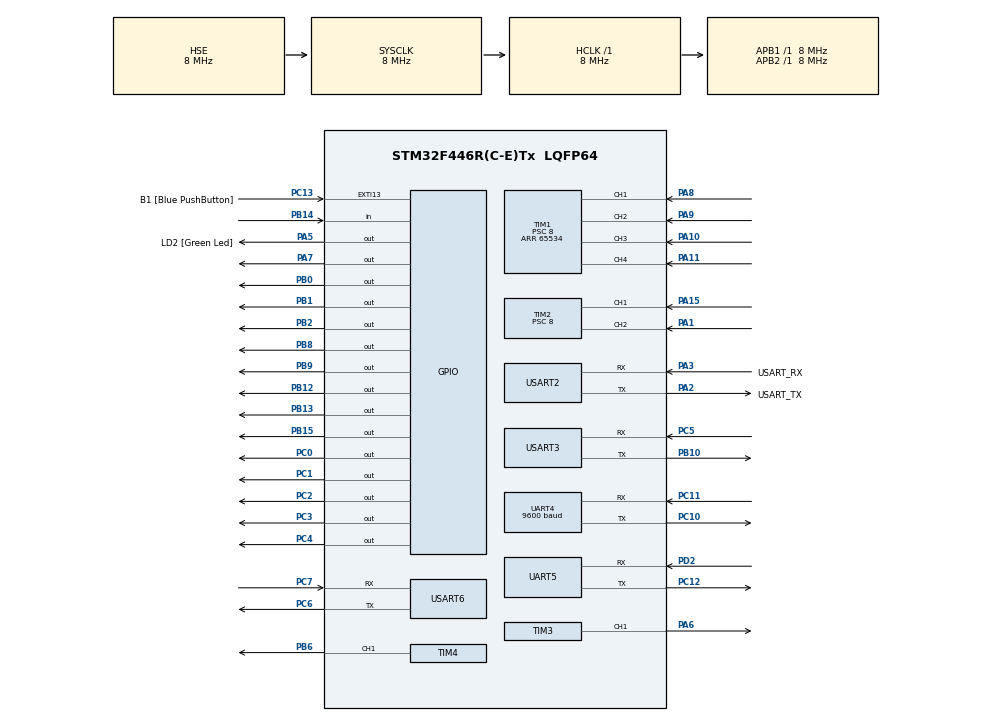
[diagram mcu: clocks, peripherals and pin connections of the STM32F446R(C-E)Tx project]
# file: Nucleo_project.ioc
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FREERTOS.HEAP_NUMBER=1
FREERTOS.Tasks01=defaultTask,0,128,StartDefaultTask,Default,NULL,Dynamic,NULL,NULL
FREERTOS.configMAX_PRIORITIES=10
FREERTOS.configUSE_NEWLIB_REENTRANT=1
Mcu.Family=STM32F4
Mcu.Name=STM32F446R(C-E)Tx
Mcu.Package=LQFP64
NVIC.PriorityGroup=NVIC_PRIORITYGROUP_4
NVIC.TIM1_CC_IRQn=true\:5\:0\:false\:false\:true\:true\:true\:true\:true
NVIC.TIM8_TRG_COM_TIM14_IRQn=true\:15\:0\:false\:false\:true\:false\:false\:true\:true
NVIC.TimeBase=TIM8_TRG_COM_TIM14_IRQn
NVIC.TimeBaseIP=TIM14
PA0-WKUP.Mode=SYS_WakeUp0
PA0-WKUP.Signal=SYS_WKUP0
PA1.Signal=S_TIM2_CH2
PA10.Signal=S_TIM1_CH3
PA11.Signal=S_TIM1_CH4
PA13.GPIO_Label=TMS
PA13.Mode=Serial_Wire
PA13.Signal=SYS_JTMS-SWDIO
PA14.GPIO_Label=TCK
PA14.Mode=Serial_Wire
PA14.Signal=SYS_JTCK-SWCLK
PA15.Signal=S_TIM2_CH1_ETR
PA2.GPIO_Label=USART_TX
PA2.Mode=Asynchronous
PA2.Signal=USART2_TX
PA3.GPIO_Label=USART_RX
PA3.Mode=Asynchronous
PA3.Signal=USART2_RX
PA5.GPIO_Label=LD2 [Green Led]
PA5.Signal=GPIO_Output
PA6.Signal=S_TIM3_CH1
PA7.Signal=GPIO_Output
PA8.Signal=S_TIM1_CH1
PA9.Signal=S_TIM1_CH2
PB0.Signal=GPIO_Output
PB1.Signal=GPIO_Output
PB10.Mode=Asynchronous
PB10.Signal=USART3_TX
PB12.Signal=GPIO_Output
PB13.Signal=GPIO_Output
PB14.Signal=GPIO_Input
PB15.Signal=GPIO_Output
PB2.Signal=GPIO_Output
PB3.GPIO_Label=SWO
PB3.Signal=SYS_JTDO-SWO
PB6.Signal=S_TIM4_CH1
PB8.Signal=GPIO_Output
PB9.Signal=GPIO_Output
PC0.Signal=GPIO_Output
PC1.Signal=GPIO_Output
PC10.Mode=Asynchronous
PC10.Signal=UART4_TX
PC11.Mode=Asynchronous
PC11.Signal=UART4_RX
PC12.Mode=Asynchronous
PC12.Signal=UART5_TX
PC13.GPIO_Label=B1 [Blue PushButton]
PC13.GPIO_ModeDefaultEXTI=GPIO_MODE_IT_FALLING
PC13.Signal=GPXTI13
PC14-OSC32_IN.Signal=RCC_OSC32_IN
PC15-OSC32_OUT.Signal=RCC_OSC32_OUT
PC2.Signal=GPIO_Output
PC3.Signal=GPIO_Output
PC4.Signal=GPIO_Output
PC5.Mode=Asynchronous
PC5.Signal=USART3_RX
PC6.Mode=Asynchronous
PC6.Signal=USART6_TX
PC7.Mode=Asynchronous
PC7.Signal=USART6_RX
PD2.Mode=Asynchronous
PD2.Signal=UART5_RX
PH0-OSC_IN.Mode=HSE-External-Oscillator
PH0-OSC_IN.Signal=RCC_OSC_IN
PH1-OSC_OUT.Mode=HSE-External-Oscillator
PH1-OSC_OUT.Signal=RCC_OSC_OUT
ProjectManager.HeapSize=0x200
ProjectManager.StackSize=0x400
ProjectManager.TargetToolchain=STM32CubeIDE
RCC.48MHZClocksFreq_Value=84000000
RCC.AHBFreq_Value=8000000
RCC.APB1Freq_Value=8000000
RCC.APB1TimFreq_Value=8000000
RCC.APB2Freq_Value=8000000
RCC.APB2TimFreq_Value=8000000
RCC.CortexFreq_Value=8000000
RCC.FLatency-AdvancedSettings=FLASH_LATENCY_0
RCC.HCLKFreq_Value=8000000
RCC.HSE_VALUE=8000000
RCC.HSI_VALUE=16000000
RCC.PLLM=4
RCC.PLLN=90
RCC.PLLSourceVirtual=RCC_PLLSOURCE_HSE
RCC.SYSCLKFreq_VALUE=8000000
RCC.SYSCLKSource=RCC_SYSCLKSOURCE_HSE
RCC.USBFreq_Value=90000000
RCC.VCOOutputFreq_Value=180000000
SH.S_TIM1_CH1.0=TIM1_CH1,Input_Capture1_from_TI1
SH.S_TIM1_CH2.0=TIM1_CH2,Input_Capture2_from_TI2
SH.S_TIM1_CH3.0=TIM1_CH3,Input_Capture3_from_TI3
SH.S_TIM1_CH4.0=TIM1_CH4,Input_Capture4_from_TI4
SH.S_TIM2_CH1_ETR.0=TIM2_CH1,Input_Capture1_from_TI1
SH.S_TIM2_CH2.0=TIM2_CH2,Input_Capture2_from_TI2
SH.S_TIM3_CH1.0=TIM3_CH1,PWM Generation1 CH1
SH.S_TIM4_CH1.0=TIM4_CH1,PWM Generation1 CH1
TIM1.Channel-Input_Capture1_from_TI1=TIM_CHANNEL_1
TIM1.Channel-Input_Capture2_from_TI2=TIM_CHANNEL_2
TIM1.Channel-Input_Capture3_from_TI3=TIM_CHANNEL_3
TIM1.Channel-Input_Capture4_from_TI4=TIM_CHANNEL_4
TIM1.CounterMode=TIM_COUNTERMODE_UP
TIM1.Period=65534
TIM1.Prescaler=8
TIM2.Channel-Input_Capture1_from_TI1=TIM_CHANNEL_1
TIM2.Channel-Input_Capture2_from_TI2=TIM_CHANNEL_2
TIM2.Period=65434
TIM2.Prescaler=8
TIM3.AutoReloadPreload=TIM_AUTORELOAD_PRELOAD_ENABLE
TIM3.Channel-PWM\ Generation1\ CH1=TIM_CHANNEL_1
TIM3.Period=20000
TIM3.Prescaler=8
TIM4.AutoReloadPreload=TIM_AUTORELOAD_PRELOAD_ENABLE
TIM4.Channel-PWM\ Generation1\ CH1=TIM_CHANNEL_1
TIM4.Period=100
TIM4.Prescaler=4
UART4.BaudRate=9600
UART4.VirtualMode=Asynchronous
UART5.VirtualMode=Asynchronous
USART2.VirtualMode=VM_ASYNC
USART3.VirtualMode=VM_ASYNC
USART6.VirtualMode=VM_ASYNC
VP_FREERTOS_VS_CMSIS_V1.Mode=CMSIS_V1
VP_SYS_VS_tim14.Mode=TIM14
VP_TIM3_VS_ClockSourceINT.Mode=Internal
VP_TIM4_VS_ClockSourceINT.Mode=Internal
board=NUCLEO-F446RE

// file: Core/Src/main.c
/* USER CODE BEGIN Header */
/**
  ******************************************************************************
  * @file           : main.c
  * @brief          : Main program body
  ******************************************************************************
  * @attention
  *
  * Copyright (c) 2024 STMicroelectronics.
  * All rights reserved.
  *
  * This software is licensed under terms that can be found in the LICENSE file
  * in the root directory of this software component.
  * If no LICENSE file comes with this software, it is provided AS-IS.
  *
  ******************************************************************************
  */
/* USER CODE END Header */
#include "main.h"
#include "cmsis_os.h"
#include "tim.h"
#include "usart.h"
#include "gpio.h"

/* USER CODE BEGIN Includes */
#include "RC_Car_App_Int.h"
/* USER CODE END Includes */

void SystemClock_Config(void);
void MX_FREERTOS_Init(void);

int main(void)
{

  /* MCU Configuration--------------------------------------------------------*/

  /* Reset of all peripherals, Initializes the Flash interface and the Systick. */
  HAL_Init();

  /* Configure the system clock */
  SystemClock_Config();

  /* Initialize all configured peripherals */
  MX_GPIO_Init();
  MX_USART2_UART_Init();
  MX_TIM1_Init();
  MX_UART4_Init();
  MX_TIM4_Init();
  MX_TIM2_Init();
  MX_TIM3_Init();
  MX_UART5_Init();
  MX_USART3_UART_Init();
  MX_USART6_UART_Init();
  /* USER CODE BEGIN 2 */

  RC_SystemInit() ;
  xTaskCreate(&T1_UartReceive  				, "UART"     , 200 , NULL ,  9  , NULL   );
  xTaskCreate(&T2_SignalsAction				, "Signals"  , 200 , NULL ,  8  , NULL   );
  xTaskCreate(&T3_WhiteFrontLightFlashing	, "flashing" , 200 , NULL ,  7  , NULL   );
  xTaskCreate(&T4_HornBeeping				, "Horn"	 , 200 , NULL ,  6  , NULL   ) ;
  xTaskCreate(&T5_ChangeGear				, "Gear"	 , 200 , NULL ,  5  , NULL   ) ;
  xTaskCreate(&T6_IncSpeed				    , "Inc"	 	 , 200 , NULL ,  4  , NULL   ) ;
  xTaskCreate(&T7_BrakeWheel				, "brake"	 , 200 , NULL ,  3  , NULL   ) ;
  xTaskCreate(&T8_CarMoveRight				, "Right"	 , 200 , NULL ,  2  , NULL   ) ;
  xTaskCreate(&T9_CarMoveLeft				, "left"	 , 200 , NULL ,  1  , NULL   ) ;

  /* USER CODE END 2 */

  /* Call init function for freertos objects (in freertos.c) */
  MX_FREERTOS_Init();

  /* Start scheduler */
  osKernelStart();

  /* We should never get here as control is now taken by the scheduler */
  /* Infinite loop */
  while (1)
  {

  }
}

void SystemClock_Config(void)
{
  RCC_OscInitTypeDef RCC_OscInitStruct = {0};
  RCC_ClkInitTypeDef RCC_ClkInitStruct = {0};

  /** Configure the main internal regulator output voltage
  */
  __HAL_RCC_PWR_CLK_ENABLE();
  __HAL_PWR_VOLTAGESCALING_CONFIG(PWR_REGULATOR_VOLTAGE_SCALE3);

  /** Initializes the RCC Oscillators according to the specified parameters
  * in the RCC_OscInitTypeDef structure.
  */
  RCC_OscInitStruct.OscillatorType = RCC_OSCILLATORTYPE_HSE;
  RCC_OscInitStruct.HSEState = RCC_HSE_ON;
  RCC_OscInitStruct.PLL.PLLState = RCC_PLL_NONE;
  if (HAL_RCC_OscConfig(&RCC_OscInitStruct) != HAL_OK)
  {
    Error_Handler();
  }

  /** Initializes the CPU, AHB and APB buses clocks
  */
  RCC_ClkInitStruct.ClockType = RCC_CLOCKTYPE_HCLK|RCC_CLOCKTYPE_SYSCLK
                              |RCC_CLOCKTYPE_PCLK1|RCC_CLOCKTYPE_PCLK2;
  RCC_ClkInitStruct.SYSCLKSource = RCC_SYSCLKSOURCE_HSE;
  RCC_ClkInitStruct.AHBCLKDivider = RCC_SYSCLK_DIV1;
  RCC_ClkInitStruct.APB1CLKDivider = RCC_HCLK_DIV1;
  RCC_ClkInitStruct.APB2CLKDivider = RCC_HCLK_DIV1;

  if (HAL_RCC_ClockConfig(&RCC_ClkInitStruct, FLASH_LATENCY_0) != HAL_OK)
  {
    Error_Handler();
  }
}

void HAL_TIM_PeriodElapsedCallback(TIM_HandleTypeDef *htim)
{
  if (htim->Instance == TIM14) {
    HAL_IncTick();
  }
}

void Error_Handler(void)
{
  __disable_irq();
  while (1)
  {
  }
}
